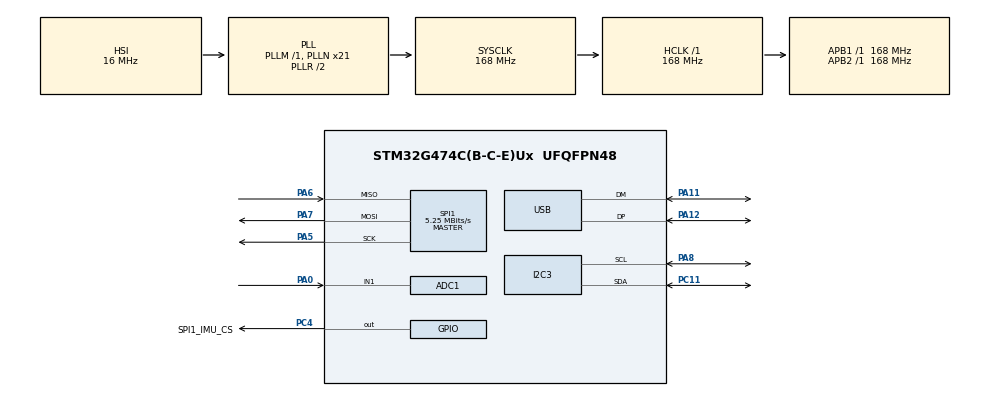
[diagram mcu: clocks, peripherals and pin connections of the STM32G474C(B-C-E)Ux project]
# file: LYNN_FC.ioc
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ADC1.Channel-0\#ChannelRegularConversion=ADC_CHANNEL_1
ADC1.ClockPrescaler=ADC_CLOCK_ASYNC_DIV4
ADC1.NbrOfConversionFlag=1
ADC1.OffsetNumber-0\#ChannelRegularConversion=ADC_OFFSET_NONE
ADC1.Overrun=ADC_OVR_DATA_OVERWRITTEN
ADC1.Rank-0\#ChannelRegularConversion=1
ADC1.SamplingTime-0\#ChannelRegularConversion=ADC_SAMPLETIME_2CYCLES_5
ADC1.master=1
Dma.Request0=SPI1_RX
Dma.Request1=SPI1_TX
Dma.SPI1_RX.0.Direction=DMA_PERIPH_TO_MEMORY
Dma.SPI1_RX.0.EventEnable=DISABLE
Dma.SPI1_RX.0.Instance=DMA1_Channel1
Dma.SPI1_RX.0.MemDataAlignment=DMA_MDATAALIGN_BYTE
Dma.SPI1_RX.0.MemInc=DMA_MINC_ENABLE
Dma.SPI1_RX.0.Mode=DMA_NORMAL
Dma.SPI1_RX.0.PeriphDataAlignment=DMA_PDATAALIGN_BYTE
Dma.SPI1_RX.0.PeriphInc=DMA_PINC_DISABLE
Dma.SPI1_RX.0.Polarity=HAL_DMAMUX_REQ_GEN_RISING
Dma.SPI1_RX.0.Priority=DMA_PRIORITY_HIGH
Dma.SPI1_RX.0.RequestNumber=1
Dma.SPI1_RX.0.SignalID=NONE
Dma.SPI1_RX.0.SyncEnable=DISABLE
Dma.SPI1_RX.0.SyncPolarity=HAL_DMAMUX_SYNC_NO_EVENT
Dma.SPI1_RX.0.SyncRequestNumber=1
Dma.SPI1_RX.0.SyncSignalID=NONE
Dma.SPI1_TX.1.Direction=DMA_MEMORY_TO_PERIPH
Dma.SPI1_TX.1.EventEnable=DISABLE
Dma.SPI1_TX.1.Instance=DMA1_Channel2
Dma.SPI1_TX.1.MemDataAlignment=DMA_MDATAALIGN_BYTE
Dma.SPI1_TX.1.MemInc=DMA_MINC_ENABLE
Dma.SPI1_TX.1.Mode=DMA_NORMAL
Dma.SPI1_TX.1.PeriphDataAlignment=DMA_PDATAALIGN_BYTE
Dma.SPI1_TX.1.PeriphInc=DMA_PINC_DISABLE
Dma.SPI1_TX.1.Polarity=HAL_DMAMUX_REQ_GEN_RISING
Dma.SPI1_TX.1.Priority=DMA_PRIORITY_HIGH
Dma.SPI1_TX.1.RequestNumber=1
Dma.SPI1_TX.1.SignalID=NONE
Dma.SPI1_TX.1.SyncEnable=DISABLE
Dma.SPI1_TX.1.SyncPolarity=HAL_DMAMUX_SYNC_NO_EVENT
Dma.SPI1_TX.1.SyncRequestNumber=1
Dma.SPI1_TX.1.SyncSignalID=NONE
FREERTOS.Tasks01=FlightLoopTask,48,1024,StartFlightLoop,Default,NULL,Dynamic,NULL,NULL
FREERTOS.configCHECK_FOR_STACK_OVERFLOW=2
FREERTOS.configENABLE_FPU=1
FREERTOS.configTOTAL_HEAP_SIZE=32000
FREERTOS.configUSE_MALLOC_FAILED_HOOK=1
FREERTOS.configUSE_NEWLIB_REENTRANT=1
I2C3.Timing=0x50916E9F
Mcu.Family=STM32G4
Mcu.Name=STM32G474C(B-C-E)Ux
Mcu.Package=UFQFPN48
NVIC.DMA1_Channel1_IRQn=true\:5\:0\:false\:false\:true\:true\:false\:true\:true
NVIC.DMA1_Channel2_IRQn=true\:5\:0\:false\:false\:true\:true\:false\:true\:true
NVIC.PriorityGroup=NVIC_PRIORITYGROUP_4
NVIC.SPI1_IRQn=true\:5\:0\:false\:false\:true\:true\:true\:true\:true
NVIC.TIM6_DAC_IRQn=true\:5\:0\:false\:false\:true\:true\:true\:true\:true
NVIC.TIM7_DAC_IRQn=true\:15\:0\:false\:false\:true\:false\:false\:true\:true
NVIC.TimeBase=TIM7_DAC_IRQn
NVIC.TimeBaseIP=TIM7
NVIC.USB_LP_IRQn=true\:5\:0\:false\:false\:true\:true\:false\:true\:true
PA0.Mode=IN1-Single-Ended
PA0.Signal=ADC1_IN1
PA11.Mode=Device
PA11.Signal=USB_DM
PA12.Mode=Device
PA12.Signal=USB_DP
PA13.Mode=Serial_Wire
PA13.Signal=SYS_JTMS-SWDIO
PA14.Mode=Serial_Wire
PA14.Signal=SYS_JTCK-SWCLK
PA5.Mode=Full_Duplex_Master
PA5.Signal=SPI1_SCK
PA6.Mode=Full_Duplex_Master
PA6.Signal=SPI1_MISO
PA7.Mode=Full_Duplex_Master
PA7.Signal=SPI1_MOSI
PA8.Mode=I2C
PA8.Signal=I2C3_SCL
PC11.Mode=I2C
PC11.Signal=I2C3_SDA
PC4.GPIO_Label=SPI1_IMU_CS
PC4.PinState=GPIO_PIN_SET
PC4.Signal=GPIO_Output
ProjectManager.HeapSize=0x200
ProjectManager.StackSize=0x400
ProjectManager.TargetToolchain=STM32CubeIDE
RCC.ADC12Freq_Value=168000000
RCC.ADC345Freq_Value=168000000
RCC.AHBFreq_Value=168000000
RCC.APB1Freq_Value=168000000
RCC.APB1TimFreq_Value=168000000
RCC.APB2Freq_Value=168000000
RCC.APB2TimFreq_Value=168000000
RCC.CK48CLockSelection=RCC_USBCLKSOURCE_HSI48
RCC.CortexFreq_Value=168000000
RCC.EXTERNAL_CLOCK_VALUE=12288000
RCC.HCLKFreq_Value=168000000
RCC.HSE_VALUE=8000000
RCC.HSI48_VALUE=48000000
RCC.HSI_VALUE=16000000
RCC.LSE_VALUE=32768
RCC.PLLN=21
RCC.SYSCLKFreq_VALUE=168000000
RCC.SYSCLKSource=RCC_SYSCLKSOURCE_PLLCLK
RCC.USBFreq_Value=48000000
RCC.VCOOutputFreq_Value=336000000
SPI1.BaudRatePrescaler=SPI_BAUDRATEPRESCALER_32
SPI1.CLKPhase=SPI_PHASE_2EDGE
SPI1.CLKPolarity=SPI_POLARITY_HIGH
SPI1.CalculateBaudRate=5.25 MBits/s
SPI1.DataSize=SPI_DATASIZE_8BIT
SPI1.Direction=SPI_DIRECTION_2LINES
SPI1.Mode=SPI_MODE_MASTER
SPI1.VirtualType=VM_MASTER
TIM6.PeriodNoDither=1000-1
TIM6.Prescaler=168-1
USB_DEVICE.CLASS_NAME_FS=CDC
USB_DEVICE.VirtualMode=Cdc
USB_DEVICE.VirtualModeFS=Cdc_FS
VP_FREERTOS_VS_CMSIS_V2.Mode=CMSIS_V2
VP_SYS_VS_DBSignals.Mode=DisableDeadBatterySignals
VP_SYS_VS_tim7.Mode=TIM7
VP_TIM6_VS_ClockSourceINT.Mode=Enable_Timer
VP_USB_DEVICE_VS_USB_DEVICE_CDC_FS.Mode=CDC_FS
board=custom

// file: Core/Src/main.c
/* USER CODE BEGIN Header */
/**
 ******************************************************************************
 * @file           : main.c
 * @brief          : Main program body
 ******************************************************************************
 * @attention
 *
 * Copyright (c) 2026 STMicroelectronics.
 * All rights reserved.
 *
 * This software is licensed under terms that can be found in the LICENSE file
 * in the root directory of this software component.
 * If no LICENSE file comes with this software, it is provided AS-IS.
 *
 ******************************************************************************
 */
/* USER CODE END Header */
#include "main.h"
#include "cmsis_os.h"
#include "usb_device.h"

/* USER CODE BEGIN Includes */
#include "main_bridge.h"
/* USER CODE END Includes */

ADC_HandleTypeDef hadc1;

I2C_HandleTypeDef hi2c3;

SPI_HandleTypeDef hspi1;
DMA_HandleTypeDef hdma_spi1_rx;
DMA_HandleTypeDef hdma_spi1_tx;

TIM_HandleTypeDef htim6;

/* Definitions for FlightLoopTask */
osThreadId_t FlightLoopTaskHandle;
const osThreadAttr_t FlightLoopTask_attributes = {.name = "FlightLoopTask", .priority = (osPriority_t)osPriorityRealtime, .stack_size = 1024 * 4};

void SystemClock_Config(void);
static void MX_GPIO_Init(void);
static void MX_DMA_Init(void);
static void MX_I2C3_Init(void);
static void MX_SPI1_Init(void);
static void MX_TIM6_Init(void);
static void MX_ADC1_Init(void);
void StartFlightLoop(void *argument);

int main(void) {

    /* MCU Configuration--------------------------------------------------------*/

    /* Reset of all peripherals, Initializes the Flash interface and the Systick. */
    HAL_Init();

    /* Configure the system clock */
    SystemClock_Config();

    /* Initialize all configured peripherals */
    MX_GPIO_Init();
    MX_DMA_Init();
    MX_I2C3_Init();
    MX_SPI1_Init();
    MX_TIM6_Init();
    MX_ADC1_Init();
    /* USER CODE BEGIN 2 */
    HAL_TIM_Base_Start_IT(&htim6);
    /* USER CODE END 2 */

    /* Init scheduler */
    osKernelInitialize();

    /* Create the thread(s) */
    /* creation of FlightLoopTask */
    FlightLoopTaskHandle = osThreadNew(StartFlightLoop, NULL, &FlightLoopTask_attributes);

    /* Start scheduler */
    osKernelStart();

    /* We should never get here as control is now taken by the scheduler */

    /* Infinite loop */
    while (1) {

    }
}

void SystemClock_Config(void) {
    RCC_OscInitTypeDef RCC_OscInitStruct = {0};
    RCC_ClkInitTypeDef RCC_ClkInitStruct = {0};

    /** Configure the main internal regulator output voltage
     */
    HAL_PWREx_ControlVoltageScaling(PWR_REGULATOR_VOLTAGE_SCALE1_BOOST);

    /** Initializes the RCC Oscillators according to the specified parameters
     * in the RCC_OscInitTypeDef structure.
     */
    RCC_OscInitStruct.OscillatorType = RCC_OSCILLATORTYPE_HSI | RCC_OSCILLATORTYPE_HSI48;
    RCC_OscInitStruct.HSIState = RCC_HSI_ON;
    RCC_OscInitStruct.HSICalibrationValue = RCC_HSICALIBRATION_DEFAULT;
    RCC_OscInitStruct.HSI48State = RCC_HSI48_ON;
    RCC_OscInitStruct.PLL.PLLState = RCC_PLL_ON;
    RCC_OscInitStruct.PLL.PLLSource = RCC_PLLSOURCE_HSI;
    RCC_OscInitStruct.PLL.PLLM = RCC_PLLM_DIV1;
    RCC_OscInitStruct.PLL.PLLN = 21;
    RCC_OscInitStruct.PLL.PLLP = RCC_PLLP_DIV2;
    RCC_OscInitStruct.PLL.PLLQ = RCC_PLLQ_DIV2;
    RCC_OscInitStruct.PLL.PLLR = RCC_PLLR_DIV2;
    if (HAL_RCC_OscConfig(&RCC_OscInitStruct) != HAL_OK) {
        Error_Handler();
    }

    /** Initializes the CPU, AHB and APB buses clocks
     */
    RCC_ClkInitStruct.ClockType = RCC_CLOCKTYPE_HCLK | RCC_CLOCKTYPE_SYSCLK | RCC_CLOCKTYPE_PCLK1 | RCC_CLOCKTYPE_PCLK2;
    RCC_ClkInitStruct.SYSCLKSource = RCC_SYSCLKSOURCE_PLLCLK;
    RCC_ClkInitStruct.AHBCLKDivider = RCC_SYSCLK_DIV1;
    RCC_ClkInitStruct.APB1CLKDivider = RCC_HCLK_DIV1;
    RCC_ClkInitStruct.APB2CLKDivider = RCC_HCLK_DIV1;

    if (HAL_RCC_ClockConfig(&RCC_ClkInitStruct, FLASH_LATENCY_4) != HAL_OK) {
        Error_Handler();
    }
}

static void MX_ADC1_Init(void) {

    ADC_MultiModeTypeDef multimode = {0};
    ADC_ChannelConfTypeDef sConfig = {0};

    /** Common config
     */
    hadc1.Instance = ADC1;
    hadc1.Init.ClockPrescaler = ADC_CLOCK_ASYNC_DIV4;
    hadc1.Init.Resolution = ADC_RESOLUTION_12B;
    hadc1.Init.DataAlign = ADC_DATAALIGN_RIGHT;
    hadc1.Init.GainCompensation = 0;
    hadc1.Init.ScanConvMode = ADC_SCAN_DISABLE;
    hadc1.Init.EOCSelection = ADC_EOC_SINGLE_CONV;
    hadc1.Init.LowPowerAutoWait = DISABLE;
    hadc1.Init.ContinuousConvMode = DISABLE;
    hadc1.Init.NbrOfConversion = 1;
    hadc1.Init.DiscontinuousConvMode = DISABLE;
    hadc1.Init.ExternalTrigConv = ADC_SOFTWARE_START;
    hadc1.Init.ExternalTrigConvEdge = ADC_EXTERNALTRIGCONVEDGE_NONE;
    hadc1.Init.DMAContinuousRequests = DISABLE;
    hadc1.Init.Overrun = ADC_OVR_DATA_OVERWRITTEN;
    hadc1.Init.OversamplingMode = DISABLE;
    if (HAL_ADC_Init(&hadc1) != HAL_OK) {
        Error_Handler();
    }

    /** Configure the ADC multi-mode
     */
    multimode.Mode = ADC_MODE_INDEPENDENT;
    if (HAL_ADCEx_MultiModeConfigChannel(&hadc1, &multimode) != HAL_OK) {
        Error_Handler();
    }

    /** Configure Regular Channel
     */
    sConfig.Channel = ADC_CHANNEL_1;
    sConfig.Rank = ADC_REGULAR_RANK_1;
    sConfig.SamplingTime = ADC_SAMPLETIME_2CYCLES_5;
    sConfig.SingleDiff = ADC_SINGLE_ENDED;
    sConfig.OffsetNumber = ADC_OFFSET_NONE;
    sConfig.Offset = 0;
    if (HAL_ADC_ConfigChannel(&hadc1, &sConfig) != HAL_OK) {
        Error_Handler();
    }
}

static void MX_I2C3_Init(void) {

    hi2c3.Instance = I2C3;
    hi2c3.Init.Timing = 0x50916E9F;
    hi2c3.Init.OwnAddress1 = 0;
    hi2c3.Init.AddressingMode = I2C_ADDRESSINGMODE_7BIT;
    hi2c3.Init.DualAddressMode = I2C_DUALADDRESS_DISABLE;
    hi2c3.Init.OwnAddress2 = 0;
    hi2c3.Init.OwnAddress2Masks = I2C_OA2_NOMASK;
    hi2c3.Init.GeneralCallMode = I2C_GENERALCALL_DISABLE;
    hi2c3.Init.NoStretchMode = I2C_NOSTRETCH_DISABLE;
    if (HAL_I2C_Init(&hi2c3) != HAL_OK) {
        Error_Handler();
    }

    /** Configure Analogue filter
     */
    if (HAL_I2CEx_ConfigAnalogFilter(&hi2c3, I2C_ANALOGFILTER_ENABLE) != HAL_OK) {
        Error_Handler();
    }

    /** Configure Digital filter
     */
    if (HAL_I2CEx_ConfigDigitalFilter(&hi2c3, 0) != HAL_OK) {
        Error_Handler();
    }
}

static void MX_SPI1_Init(void) {

    /* SPI1 parameter configuration*/
    hspi1.Instance = SPI1;
    hspi1.Init.Mode = SPI_MODE_MASTER;
    hspi1.Init.Direction = SPI_DIRECTION_2LINES;
    hspi1.Init.DataSize = SPI_DATASIZE_8BIT;
    hspi1.Init.CLKPolarity = SPI_POLARITY_HIGH;
    hspi1.Init.CLKPhase = SPI_PHASE_2EDGE;
    hspi1.Init.NSS = SPI_NSS_SOFT;
    hspi1.Init.BaudRatePrescaler = SPI_BAUDRATEPRESCALER_32;
    hspi1.Init.FirstBit = SPI_FIRSTBIT_MSB;
    hspi1.Init.TIMode = SPI_TIMODE_DISABLE;
    hspi1.Init.CRCCalculation = SPI_CRCCALCULATION_DISABLE;
    hspi1.Init.CRCPolynomial = 7;
    hspi1.Init.CRCLength = SPI_CRC_LENGTH_DATASIZE;
    hspi1.Init.NSSPMode = SPI_NSS_PULSE_DISABLE;
    if (HAL_SPI_Init(&hspi1) != HAL_OK) {
        Error_Handler();
    }
}

static void MX_TIM6_Init(void) {

    TIM_MasterConfigTypeDef sMasterConfig = {0};

    htim6.Instance = TIM6;
    htim6.Init.Prescaler = 168 - 1;
    htim6.Init.CounterMode = TIM_COUNTERMODE_UP;
    htim6.Init.Period = 999;
    htim6.Init.AutoReloadPreload = TIM_AUTORELOAD_PRELOAD_DISABLE;
    if (HAL_TIM_Base_Init(&htim6) != HAL_OK) {
        Error_Handler();
    }
    sMasterConfig.MasterOutputTrigger = TIM_TRGO_RESET;
    sMasterConfig.MasterSlaveMode = TIM_MASTERSLAVEMODE_DISABLE;
    if (HAL_TIMEx_MasterConfigSynchronization(&htim6, &sMasterConfig) != HAL_OK) {
        Error_Handler();
    }
}

static void MX_DMA_Init(void) {

    /* DMA controller clock enable */
    __HAL_RCC_DMAMUX1_CLK_ENABLE();
    __HAL_RCC_DMA1_CLK_ENABLE();

    /* DMA interrupt init */
    /* DMA1_Channel1_IRQn interrupt configuration */
    HAL_NVIC_SetPriority(DMA1_Channel1_IRQn, 5, 0);
    HAL_NVIC_EnableIRQ(DMA1_Channel1_IRQn);
    /* DMA1_Channel2_IRQn interrupt configuration */
    HAL_NVIC_SetPriority(DMA1_Channel2_IRQn, 5, 0);
    HAL_NVIC_EnableIRQ(DMA1_Channel2_IRQn);
}

static void MX_GPIO_Init(void) {
    GPIO_InitTypeDef GPIO_InitStruct = {0};

    /* GPIO Ports Clock Enable */
    __HAL_RCC_GPIOA_CLK_ENABLE();
    __HAL_RCC_GPIOC_CLK_ENABLE();

    /*Configure GPIO pin Output Level */
    HAL_GPIO_WritePin(SPI1_IMU_CS_GPIO_Port, SPI1_IMU_CS_Pin, GPIO_PIN_SET);

    /*Configure GPIO pin : SPI1_IMU_CS_Pin */
    GPIO_InitStruct.Pin = SPI1_IMU_CS_Pin;
    GPIO_InitStruct.Mode = GPIO_MODE_OUTPUT_PP;
    GPIO_InitStruct.Pull = GPIO_NOPULL;
    GPIO_InitStruct.Speed = GPIO_SPEED_FREQ_LOW;
    HAL_GPIO_Init(SPI1_IMU_CS_GPIO_Port, &GPIO_InitStruct);

}

void StartFlightLoop(void *argument) {
    /* init code for USB_Device */
    MX_USB_Device_Init();
    /* USER CODE BEGIN 5 */
    /* Infinite loop */

    flight_controller_run();
    // for (;;) {
    //     osDelay(1);
    //}
    /* USER CODE END 5 */
}

void HAL_TIM_PeriodElapsedCallback(TIM_HandleTypeDef *htim) {
    if (htim->Instance == TIM7) {
        HAL_IncTick();
    }
}

void Error_Handler(void) {
    __disable_irq();
    while (1) {
    }
}
